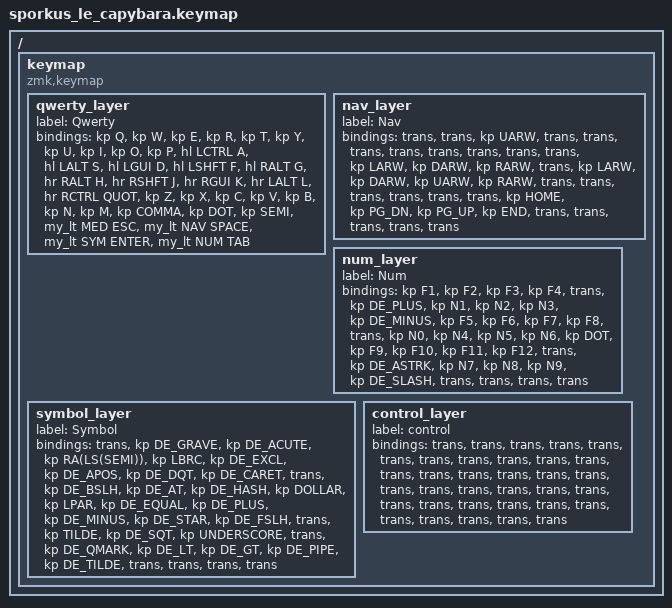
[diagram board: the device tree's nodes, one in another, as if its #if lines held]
/*
 * Copyright (c) 2020 The ZMK Contributors
 *
 * SPDX-License-Identifier: MIT
 */

#include "base_sporkus_le_capybara.h"

/ {
  //   cond_layers {
  //       compatible = "zmk,conditional-layers";
	// tri {
	//     if-layers = <NUM_L NAV_L>;
	//     then-layer = <MED_L>;
  //       };
  //   };


        keymap {
                compatible = "zmk,keymap";

#ifdef QWERTY_BASE
        qwerty_layer {
            label = "Qwerty";
            bindings = <
       &kp Q         &kp W        &kp E        &kp R         &kp T           &kp Y        &kp U         &kp I        &kp O        &kp P
       &hl LCTRL A   &hl LALT S   &hl LGUI D   &hl LSHFT F   &hl RALT G      &hr RALT H   &hr RSHFT J   &hr RGUI K   &hr LALT L   &hr RCTRL QUOT
       &kp Z         &kp X        &kp C        &kp V         &kp B           &kp N        &kp M         &kp COMMA    &kp DOT      &kp SEMI
                                        &my_lt MED ESC  &my_lt NAV SPACE  &my_lt SYM ENTER    &my_lt NUM TAB
            >;
        };
#else
        apt_layer {
            label = "Base";
            bindings = <
       &kp DE_V      &kp W        &kp F        &kp P          &kp B         &kp J         &kp L         &kp DE_Y     &kp U       &kp DE_Z
       &hl LCTRL R   &hl LALT S   &hl LGUI T   &hl LSHFT H    &hl RALT K    &hr RALT X    &hr RSHFT N   &hr RGUI A   &hr LALT I  &hr RCTRL O
       &kp Q         &kp C        &kp G        &kp D          &kp X         &kp DE_Z      &kp M         &kp DE_COMMA &kp DE_DOT  &kp DE_MINUS
                                  &my_lt MED ESC  &my_lt NAV SPACE  &my_lt SYM E        &my_lt NUM TAB
            >;
        };
#endif

        nav_layer {
            label = "Nav";
            bindings = <
       &trans     &trans     &kp UARW    &trans          &trans       &trans           &trans         &trans      &trans     &trans
       &trans     &kp LARW   &kp DARW    &kp RARW        &trans       &kp LARW         &kp DARW       &kp UARW    &kp RARW   &trans
       &trans     &trans     &trans      &trans          &trans       &kp HOME         &kp PG_DN      &kp PG_UP   &kp END    &trans
                                         &trans          &trans       &trans           &trans
            >;
        };

        num_layer {
            label = "Num";
            bindings = <
       &kp F1     &kp F2     &kp F3      &kp F4          &trans        &kp DE_PLUS   &kp N1         &kp N2      &kp N3     &kp DE_MINUS
       &kp F5     &kp F6     &kp F7      &kp F8          &trans        &kp N0        &kp N4         &kp N5      &kp N6     &kp DOT
       &kp F9     &kp F10    &kp F11     &kp F12         &trans        &kp DE_ASTRK  &kp N7         &kp N8      &kp N9     &kp DE_SLASH
                                         &trans          &trans        &trans        &trans
            >;
        };

        symbol_layer {
            label = "Symbol";
            bindings = <
       &trans         &kp DE_GRAVE   &kp DE_ACUTE   &kp RA(LS(SEMI)) &kp LBRC       &kp DE_EXCL     &kp DE_APOS    &kp DE_DQT     &kp DE_CARET   &trans
       &kp DE_BSLH    &kp DE_AT      &kp DE_HASH    &kp DOLLAR       &kp LPAR       &kp DE_EQUAL    &kp DE_PLUS    &kp DE_MINUS   &kp DE_STAR    &kp DE_FSLH
       &trans         &kp TILDE      &kp DE_SQT     &kp UNDERSCORE   &trans         &kp DE_QMARK    &kp DE_LT      &kp DE_GT      &kp DE_PIPE    &kp DE_TILDE
                                                    &trans           &trans         &trans          &trans
            >;
        };

        control_layer {
            label = "control";
            bindings = <
       &trans         &trans         &trans         &trans           &trans         &trans          &trans         &trans         &trans         &trans
       &trans         &trans         &trans         &trans           &trans         &trans          &trans         &trans         &trans         &trans
       &trans         &trans         &trans         &trans           &trans         &trans          &trans         &trans         &trans         &trans
                                                    &trans           &trans         &trans          &trans
            >;
        };

		/*
                default_layer {
// -------------------------------------------------------------------------------------
// |  TAB |  Q  |  W  |  E  |  R  |  T  |   |  Y  |  U   |  I  |  O  |  P  |   BKSP    |
// | CTRL |  A  |  S  |  D  |  F  |  G  |   |  H  |  J   |  K  |  L  |  ;  |    '      |
// | SHFT |  Z  |  X  |  C  |  V  |  B  |   |  N  |  M   |  ,  |  .  |  /  | SHFT(RET) |
//                         | ALT | LWR | SPC | RSE  | ALT |
	*/

        };
};
